AUTOSAR XML (schema 00050)
package /ComponentTypes
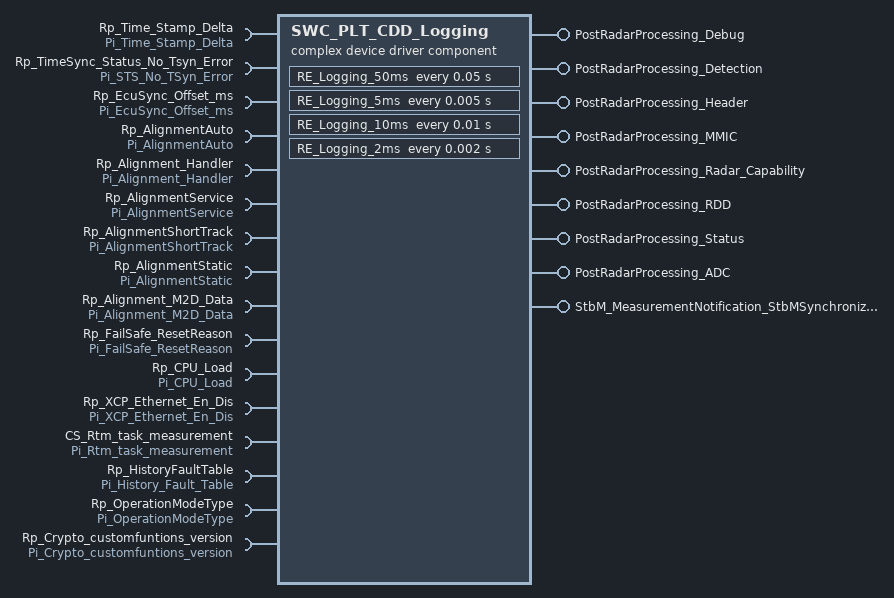
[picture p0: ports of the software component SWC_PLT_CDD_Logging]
  complex device driver sw component type SWC_PLT_CDD_Logging
    8 x provide port:
      PostRadarProcessing_Debug: server-com-spec{operation=Populate_Debug_Stream, queue-length=1}, provided-interface=PostRadarProcessing_Debug
      PostRadarProcessing_Detection: server-com-spec{operation=Populate_Detection_Stream, queue-length=1}, provided-interface=PostRadarProcessing_Detection
      PostRadarProcessing_Header: server-com-spec{operation=Populate_Header_Stream, queue-length=1}, provided-interface=PostRadarProcessing_Header
      PostRadarProcessing_MMIC: server-com-spec{operation=Populate_MMIC_Stream, queue-length=1}, provided-interface=PostRadarProcessing_MMIC
      PostRadarProcessing_Radar_Capability: server-com-spec{operation=Populate_Radar_Capability_Stream, queue-length=1}, provided-interface=PostRadarProcessing_Radar_Capability
      PostRadarProcessing_RDD: server-com-spec{operation=Populate_RDD_Stream, queue-length=1}, provided-interface=PostRadarProcessing_RDD
      PostRadarProcessing_Status: server-com-spec{operation=Populate_Status_Stream, queue-length=1}, provided-interface=PostRadarProcessing_Status
      PostRadarProcessing_ADC: server-com-spec{operation=Populate_ADC_Stream, queue-length=1}, provided-interface=PostRadarProcessing_ADC
    require port Rp_Time_Stamp_Delta: nonqueued-receiver-com-spec{data-element=De_Time_Stamp_Delta, filter=data-filter-type=ALWAYS}, required-interface=Pi_Time_Stamp_Delta
    require port Rp_TimeSync_Status_No_Tsyn_Error: nonqueued-receiver-com-spec{data-element=De_STS_No_TSyn_Error, filter=data-filter-type=ALWAYS}, required-interface=Pi_STS_No_TSyn_Error
    require port Rp_EcuSync_Offset_ms: nonqueued-receiver-com-spec{data-element=De_EcuSync_Offset_ms, filter=data-filter-type=ALWAYS}, required-interface=Pi_EcuSync_Offset_ms
    provide port StbM_MeasurementNotification_StbMSynchronizedTimeBase: server-com-spec{operation=TimeRecordBlock_Callback, queue-length=1}, provided-interface=StbM_MeasurementNotification_StbMSynchronizedTimeBase
    13 x require port:
      Rp_AlignmentAuto: nonqueued-receiver-com-spec{data-element=De_AlignmentAuto, filter=data-filter-type=ALWAYS, init-value=fields=[StartAzimuth:0, StartElevation:0, AACurrentAzimuth:0, AACurrentElevation:0, AAAzimuthStd:0, AAElevationStd:0, AARollStd:0, Az_Err_positive:0, Az_Err_negative:0, El_Err_positive:0, El_Err_negative:0, RollError_positive:0, RollError_negative:0, HostScf:0, AzimuthNumUpdates:0, ElevationNumUpdates:0, AutoAlignmentFailRootCause:0, AlignAutoStatus:0, HostScf_QF:0, StartRoll:0, AACurrentRoll:0, RollUpdates:0]}, required-interface=Pi_AlignmentAuto
      Rp_Alignment_Handler: nonqueued-receiver-com-spec{data-element=De_Alignment_Handler, filter=data-filter-type=ALWAYS, init-value=fields=[0, 0, 0, 0, 0, AlignmentAzimuth:0, AlignmentElevation:0, AzimuthStd:0, ElevationStd:0, calTime:0, CalDisplay:0, ProgressPercent:0, AlignmentError:0, ElevationQuality:0, AzimuthQuality:0, Alignment_modeIn:0, AlignmentModeOut:0, 0, Radar_Type_Input:0, CoordinateSystem_Input:0, 0, 0, AlignmentRoll:0, RollStd:0]}, required-interface=Pi_Alignment_Handler
      Rp_AlignmentService: nonqueued-receiver-com-spec{data-element=De_AlignmentService, filter=data-filter-type=ALWAYS, init-value=fields=[DistanceAbsolute:0, DistanceEffective:0, AvgNumOfDet:0, DurationAbsolute:0, DurationEffective:0, AverageSpeed:0, AlignmentServiceSt:0, VehicleCondition:0]}, required-interface=Pi_AlignmentService
      Rp_AlignmentShortTrack: nonqueued-receiver-com-spec{data-element=De_AlignmentShortTrack, filter=data-filter-type=ALWAYS, init-value=fields=AlignShortTrackSt:0}, required-interface=Pi_AlignmentShortTrack
      Rp_AlignmentStatic: nonqueued-receiver-com-spec{data-element=De_AlignmentStatic, filter=data-filter-type=ALWAYS, init-value=fields=[MeasuredAzimuth:0, MeasuredElevation:0, Measured_Az_Std:0, Measured_El_Std:0, MeasuredRange:0, MeasuredRangeStd:0, MeasuredRangeRate:0, MeasuredRangeRateStd:0, MeasuredAmplitude:0, MeasuredAmpStd:0, AlignmentStaticStatus:0, StatusOfPlate:0, StatusOfAzimuth:0, StatusOfElevation:0, ImpactByInterference:0]}, required-interface=Pi_AlignmentStatic
      Rp_Alignment_M2D_Data: nonqueued-receiver-com-spec{data-element=De_Alignment_M2D_Data, filter=data-filter-type=ALWAYS, init-value=fields=[{short-label=static_alignment_data, fields=[yaw:0, pitch:0, plate_angle_deg_scs:0, plate_distance:0, polarity:0, horz_angle_min:0, horz_angle_max:0, vert_angle_min:0, vert_angle_max:0, plate_lat_position:0, mount_loc:0, align_cmd:0, max_abs_misalignment_az:0, max_abs_misalignment_el_sky:0, max_abs_misalignment_el_ground:0, target_height_over_ground:0, k_num_valid_scan_needed:0, k_max_number_of_scans_allowed:0, target_range_rate:0, target_type_select:0, f_data_valid:0]}, {short-label=dynamic_alignment_data, fields=[0, 0, 0, max_abs_misalignment_az:0, short_track_target_height:0, short_track_target_range_rate:0, az_scf_kf_covariance:[0, 0, 0, 0], el_kf_covariance:0, iso_sensor_x_posn:0, iso_sensor_y_posn:0, iso_sensor_z_posn:0, iso_sensor_yaw:0, iso_sensor_pitch:0, iso_sensor_roll:0, distance_rear_axle_to_front_bumper:0, max_abs_misalignment_el_sky:0, max_abs_misalignment_el_ground:0, aacurrent_azimuth:0, aacurrent_elevation:0, 0, 0, mount_loc:0, short_track_exit_condition:0, f_data_valid:0, 0, 0, align_cmd:0, auto_align_status:0, 0, 0, el_roll_kf_covariance:[0, 0, 0, 0], Align_RadarOperation_Mode:0, coordinate_system_input:0]}]}, required-interface=Pi_Alignment_M2D_Data
      Rp_FailSafe_ResetReason: nonqueued-receiver-com-spec{data-element=De_FailSafe_ResetReason, filter=data-filter-type=ALWAYS, init-value=constant-reference=C_FailSafe_ResetReason_T}, required-interface=Pi_FailSafe_ResetReason
      Rp_CPU_Load: nonqueued-receiver-com-spec{data-element=De_CPU_Load, filter=data-filter-type=ALWAYS, init-value=fields=[CPU_Load:0, CPU_Load_Max:0, CPU_Load_Min:0, CPU_Load_Avg:0]}, required-interface=Pi_CPU_Load
      Rp_XCP_Ethernet_En_Dis: nonqueued-receiver-com-spec{data-element=De_XCP_Ethernet_En_Dis, filter=data-filter-type=ALWAYS, init-value=0}, required-interface=Pi_XCP_Ethernet_En_Dis
      CS_Rtm_task_measurement: client-com-spec=Operation, required-interface=Pi_Rtm_task_measurement
      Rp_HistoryFaultTable: nonqueued-receiver-com-spec{data-element=De_HistoryFaultTable, filter=data-filter-type=ALWAYS, init-value=constant-reference=C_Fault_T}, required-interface=Pi_History_Fault_Table
      Rp_OperationModeType: nonqueued-receiver-com-spec{data-element=De_OperationMode_System, filter=data-filter-type=ALWAYS, init-value=0}, required-interface=Pi_OperationModeType
      Rp_Crypto_customfuntions_version: nonqueued-receiver-com-spec{data-element=De_Crypto_CustomFunctions_Version, filter=data-filter-type=ALWAYS, init-value=fields=[containerVersion:0, mwVersion:0, sBoot:0]}, required-interface=Pi_Crypto_customfuntions_version
    behavior SWC_PLT_CDD_Logging_InternalBehavior: handle-termination-and-restart=NO-SUPPORT
      timing event TMT_RE_Logging_50ms: start-on-event=RE_Logging_50ms, period=0.05
      timing event TMT_RE_Logging_5ms: start-on-event=RE_Logging_5ms, period=0.005
      init event RE_Logging_InitEvent: start-on-event=RE_Logging_Init
      8 x operation invoked event:
        OIT_PostRadarProcessing_Debug_Populate_Debug_Stream_PostRadarProcessing_Debug_Populate_Debug_Stream: start-on-event=PostRadarProcessing_Debug_Populate_Debug_Stream, operation=PostRadarProcessing_Debug.Populate_Debug_Stream
        OIT_PostRadarProcessing_Detection_Populate_Detection_Stream_PostRadarProcessing_Detection_Populate_Detection_Stream: start-on-event=PostRadarProcessing_Detection_Populate_Detection_Stream, operation=PostRadarProcessing_Detection.Populate_Detection_Stream
        OIT_PostRadarProcessing_Header_Populate_Header_Stream_PostRadarProcessing_Header_Populate_Header_Stream: start-on-event=PostRadarProcessing_Header_Populate_Header_Stream, operation=PostRadarProcessing_Header.Populate_Header_Stream
        OIT_PostRadarProcessing_MMIC_Populate_MMIC_Stream_PostRadarProcessing_MMIC_Populate_MMIC_Stream: start-on-event=PostRadarProcessing_MMIC_Populate_MMIC_Stream, operation=PostRadarProcessing_MMIC.Populate_MMIC_Stream
        OIT_PostRadarProcessing_Radar_Capability_Populate_Radar_Capability_Stream_PostRadarProcessing_Radar_Capability_Populate_4F329E1C: start-on-event=PostRadarProcessing_Radar_Capability_Populate_Radar_Capability_Stream, operation=PostRadarProcessing_Radar_Capability.Populate_Radar_Capability_Stream
        OIT_PostRadarProcessing_RDD_Populate_RDD_Stream_PostRadarProcessing_RDD_Populate_RDD_Stream: start-on-event=PostRadarProcessing_RDD_Populate_RDD_Stream, operation=PostRadarProcessing_RDD.Populate_RDD_Stream
        OIT_PostRadarProcessing_Status_Populate_Status_Stream_PostRadarProcessing_Status_Populate_Status_Stream: start-on-event=PostRadarProcessing_Status_Populate_Status_Stream, operation=PostRadarProcessing_Status.Populate_Status_Stream
        OIT_PostRadarProcessing_ADC_Populate_ADC_Stream_PostRadarProcessing_ADC_Populate_ADC_Stream: start-on-event=PostRadarProcessing_ADC_Populate_ADC_Stream, operation=PostRadarProcessing_ADC.Populate_ADC_Stream
      timing event TMT_RE_Logging_10ms: start-on-event=RE_Logging_10ms, period=0.01
      operation invoked event OIT_StbM_MeasurementNotification_StbMSynchronizedTimeBase_TimeRecordBlock_Callback_StbM_MeasurementNotification_StbMSync71EECD83: start-on-event=StbM_MeasurementNotification_StbMSynchronizedTimeBase_TimeRecordBlock_Callback, operation=StbM_MeasurementNotification_StbMSynchronizedTimeBase.TimeRecordBlock_Callback
      timing event TMT_RE_Logging_2ms: start-on-event=RE_Logging_2ms, period=0.002
      14 x runnable:
        RE_Logging_50ms
          data-receive-point-by-arguments:
            12 x access:
              REC_Rp_AlignmentAuto_De_AlignmentAuto: accessed-variable=Rp_AlignmentAuto.De_AlignmentAuto
              REC_Rp_AlignmentService_De_AlignmentService: accessed-variable=Rp_AlignmentService.De_AlignmentService
              REC_Rp_AlignmentShortTrack_De_AlignmentShortTrack: accessed-variable=Rp_AlignmentShortTrack.De_AlignmentShortTrack
              REC_Rp_AlignmentStatic_De_AlignmentStatic: accessed-variable=Rp_AlignmentStatic.De_AlignmentStatic
              REC_Rp_Alignment_Handler_De_Alignment_Handler: accessed-variable=Rp_Alignment_Handler.De_Alignment_Handler
              REC_Rp_Alignment_M2D_Data_De_Alignment_M2D_Data: accessed-variable=Rp_Alignment_M2D_Data.De_Alignment_M2D_Data
              REC_Rp_FailSafe_ResetReason_De_FailSafe_ResetReason: accessed-variable=Rp_FailSafe_ResetReason.De_FailSafe_ResetReason
              REC_Rp_CPU_Load_De_CPU_Load: accessed-variable=Rp_CPU_Load.De_CPU_Load
              REC_Rp_XCP_Ethernet_En_Dis_De_XCP_Ethernet_En_Dis: accessed-variable=Rp_XCP_Ethernet_En_Dis.De_XCP_Ethernet_En_Dis
              REC_Rp_HistoryFaultTable_De_HistoryFaultTable: accessed-variable=Rp_HistoryFaultTable.De_HistoryFaultTable
              REC_Rp_OperationModeType_De_OperationMode_System: accessed-variable=Rp_OperationModeType.De_OperationMode_System
              REC_Rp_Crypto_customfuntions_version_De_Crypto_CustomFunctions_Version: accessed-variable=Rp_Crypto_customfuntions_version.De_Crypto_CustomFunctions_Version
          sync call SC_CS_Rtm_task_measurement_Operation: operation=CS_Rtm_task_measurement.Operation
        RE_Logging_5ms
        RE_Logging_Init
        PostRadarProcessing_Debug_Populate_Debug_Stream
        PostRadarProcessing_Detection_Populate_Detection_Stream
        PostRadarProcessing_Header_Populate_Header_Stream
        PostRadarProcessing_MMIC_Populate_MMIC_Stream
        PostRadarProcessing_Radar_Capability_Populate_Radar_Capability_Stream
        PostRadarProcessing_RDD_Populate_RDD_Stream
        PostRadarProcessing_Status_Populate_Status_Stream
        PostRadarProcessing_ADC_Populate_ADC_Stream
        RE_Logging_10ms
        StbM_MeasurementNotification_StbMSynchronizedTimeBase_TimeRecordBlock_Callback
        RE_Logging_2ms
  swc implementation SWC_PLT_CDD_Logging_Implementation: behavior=SWC_PLT_CDD_Logging_InternalBehavior
    resource consumption ResourceConsumption
      5 x memory section, all with sw-addrmethod=CODE:
        CODE
        VAR_SAVED_ZONE
        VAR_NOINIT_UNSPECIFIED
        VAR_INIT_UNSPECIFIED
        VAR_ZERO_INIT_UNSPECIFIED
